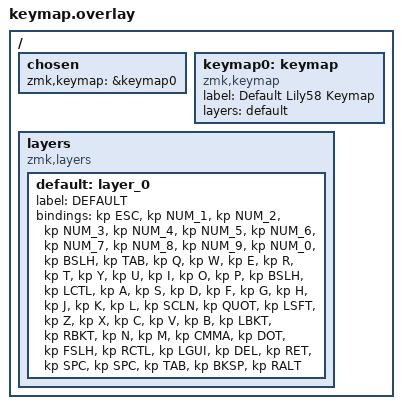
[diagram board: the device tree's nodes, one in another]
#include <behaviors.dtsi>
#include <dt-bindings/zmk/keys.h>
#include <dt-bindings/zmk/matrix-transform.h>

/ {
	chosen {
		zmk,keymap = &keymap0;
	};
	
	keymap0: keymap {
		compatible = "zmk,keymap";
		label ="Default Lily58 Keymap";
		layers = <&default>;
	};

	layers {
		compatible = "zmk,layers";

		default: layer_0 {
			label = "DEFAULT";
// ---------------------------------------------------------------------------------------------------------------------------------
// |  ESC  |  1  |  2  |  3   |  4   |  5   |                   |  6   |  7    |  8    |  9   |   0   |  `   |
// |  TAB  |  Q  |  W  |  E   |  R   |  T   |                   |  Y   |  U    |  I    |  O   |   P   |  \   |
// |  CTRL |  A  |  S  |  D   |  F   |  G   |                   |  H   |  J    |  K    |  L   |   ;   |   '  |
// | SHIFT |  Z  |  X  |  C   |  V   |  B   |   "["  |  |  "]"  |  N   |  M    |  ,    |  .   |   /   | CTRL |
//                     | GUI  | DEL  | RET  |  SPACE |  | SPACE | TAB  | BSPC  | R-ALT |
			bindings = <
&kp ESC  &kp NUM_1 &kp NUM_2 &kp NUM_3 &kp NUM_4 &kp NUM_5                    &kp NUM_6 &kp NUM_7 &kp NUM_8 &kp NUM_9 &kp NUM_0 &kp BSLH
&kp TAB  &kp Q     &kp W     &kp E     &kp R     &kp T                        &kp Y     &kp U     &kp I     &kp O     &kp P     &kp BSLH
&kp LCTL &kp A     &kp S     &kp D     &kp F     &kp G                        &kp H     &kp J     &kp K     &kp L     &kp SCLN  &kp QUOT
&kp LSFT &kp Z     &kp X     &kp C     &kp V     &kp B     &kp LBKT  &kp RBKT &kp N     &kp M     &kp CMMA  &kp DOT   &kp FSLH  &kp RCTL
	                     &kp LGUI &kp DEL  &kp RET &kp SPC                 &kp SPC  &kp TAB  &kp BKSP &kp RALT
			>;
		};
	};
};
